VERSION ""

NS_ :

BS_:

BU_: AUT REF_ECU

BO_ 2181038088 F_EXT_0x2000008: 8 REF_ECU
 SG_ S_EXT_0x2000008_2_S32 : 39|32@0- (1,0) [-32768|32767] ""  AUT
 SG_ S_EXT_0x2000008_1_S32 : 0|32@1- (1,0) [-32768|32767] ""  AUT

BO_ 2181038087 F_EXT_0x2000007: 7 REF_ECU
 SG_ S_EXT_0x2000007_S24 : 39|24@0- (1,0) [-8388608|8388607] ""  AUT
 SG_ S_EXT_0x2000007_S32 : 7|32@0- (1,0) [-2147483648|2147483647] ""  AUT

BO_ 2181038086 F_EXT_0x2000006: 6 REF_ECU
 SG_ S_EXT_0x2000006_S16 : 39|16@0+ (1,0) [0|65535] ""  AUT
 SG_ S_EXT_0x2000006_S32 : 7|32@0- (1,0) [-2147483648|2147483647] ""  AUT

BO_ 2181038085 F_EXT_0x2000005: 5 REF_ECU
 SG_ S_EXT_0x2000005_S8 : 39|8@0+ (1,0) [0|255] ""  AUT
 SG_ S_EXT_0x2000005_S32 : 7|32@0- (1,0) [-2147483648|2147483647] ""  AUT

BO_ 2181038084 F_EXT_0x2000004: 4 REF_ECU
 SG_ S_EXT_0x2000004_S32 : 7|32@0+ (1,0) [0|4294967295] ""  AUT

BO_ 2181038083 F_EXT_0x2000003: 3 REF_ECU
 SG_ S_EXT_0x2000003_S24 : 7|24@0- (1,0) [-8388608|8388607] ""  AUT

BO_ 2181038082 F_EXT_0x2000002: 2 REF_ECU
 SG_ S_EXT_0x2000002_S16 : 7|16@0- (1,0) [-32768|32767] ""  AUT

BO_ 2181038081 F_EXT_0x2000001: 1 REF_ECU
 SG_ S_EXT_0x2000001_S8 : 7|8@0- (1,0) [-128|127] ""  AUT

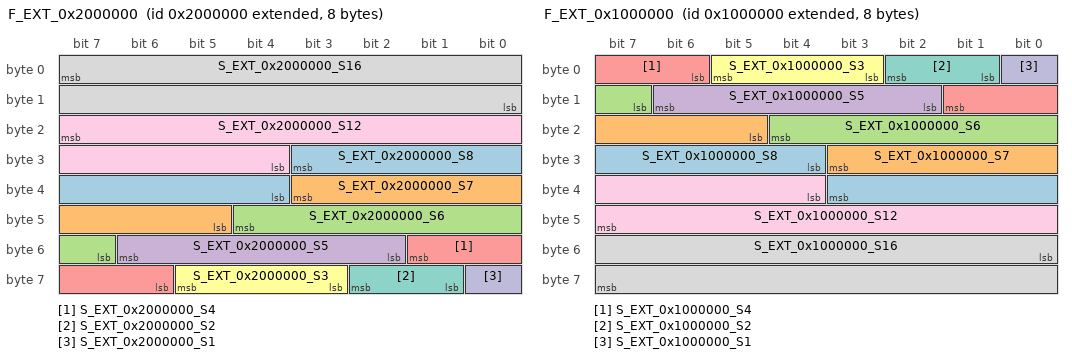
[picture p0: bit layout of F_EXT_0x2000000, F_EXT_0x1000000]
BO_ 2181038080 F_EXT_0x2000000: 8 REF_ECU
 SG_ S_EXT_0x2000000_S8 : 27|8@0- (1,0) [-128|127] ""  AUT
 SG_ S_EXT_0x2000000_S7 : 35|7@0- (1,0) [-64|63] ""  AUT
 SG_ S_EXT_0x2000000_S6 : 44|6@0- (1,0) [-32|31] ""  AUT
 SG_ S_EXT_0x2000000_S5 : 54|5@0- (1,0) [-16|15] ""  AUT
 SG_ S_EXT_0x2000000_S4 : 49|4@0- (1,0) [-8|7] ""  AUT
 SG_ S_EXT_0x2000000_S3 : 61|3@0- (1,0) [-4|3] ""  AUT
 SG_ S_EXT_0x2000000_S2 : 58|2@0- (1,0) [-2|1] ""  AUT
 SG_ S_EXT_0x2000000_S16 : 7|16@0- (1,0) [-32768|32767] ""  AUT
 SG_ S_EXT_0x2000000_S12 : 23|12@0- (1,0) [-2048|2047] ""  AUT
 SG_ S_EXT_0x2000000_S1 : 56|1@0- (1,0) [-1|0] ""  AUT

BO_ 2164260872 F_EXT_0x1000008: 8 REF_ECU
 SG_ S_EXT_0x1000008_2_S32 : 32|32@1+ (1,0) [0|4294967295] ""  AUT
 SG_ S_EXT_0x1000008_1_S32 : 0|32@1+ (1,0) [0|4294970000] ""  AUT

BO_ 2164260871 F_EXT_0x1000007: 7 REF_ECU
 SG_ S_EXT_0x1000007_S24 : 32|24@1+ (1,0) [0|16777215] ""  AUT
 SG_ S_EXT_0x1000007_S32 : 0|32@1+ (1,0) [0|4294967295] ""  AUT

BO_ 2164260870 F_EXT_0x1000006: 6 REF_ECU
 SG_ S_EXT_0x1000006_S16 : 32|16@1- (1,0) [-32768|32767] ""  AUT
 SG_ S_EXT_0x1000006_S32 : 0|32@1+ (1,0) [0|4294967295] ""  AUT

BO_ 2164260869 F_EXT_0x1000005: 5 REF_ECU
 SG_ S_EXT_0x1000005_S8 : 32|8@1- (1,0) [-128|127] ""  AUT
 SG_ S_EXT_0x1000005_S32 : 0|32@1+ (1,0) [0|4294967295] ""  AUT

BO_ 2164260868 F_EXT_0x1000004: 4 REF_ECU
 SG_ S_EXT_0x1000004_S32 : 0|32@1- (1,0) [-2147483648|2147483647] ""  AUT

BO_ 2164260867 F_EXT_0x1000003: 3 REF_ECU
 SG_ S_EXT_0x1000003_S24 : 0|24@1+ (1,0) [0|16777215] ""  AUT

BO_ 2164260866 F_EXT_0x1000002: 2 REF_ECU
 SG_ S_EXT_0x1000002_S16 : 0|16@1+ (1,0) [0|65535] ""  AUT

BO_ 2164260865 F_EXT_0x1000001: 1 REF_ECU
 SG_ S_EXT_0x1000001_S8 : 0|8@1+ (1,0) [0|255] ""  AUT

BO_ 2164260864 F_EXT_0x1000000: 8 REF_ECU
 SG_ S_EXT_0x1000000_S8 : 28|8@1+ (1,0) [0|255] ""  AUT
 SG_ S_EXT_0x1000000_S7 : 21|7@1+ (1,0) [0|127] ""  AUT
 SG_ S_EXT_0x1000000_S6 : 15|6@1+ (1,0) [0|63] ""  AUT
 SG_ S_EXT_0x1000000_S5 : 10|5@1+ (1,0) [0|31] ""  AUT
 SG_ S_EXT_0x1000000_S4 : 6|4@1+ (1,0) [0|15] ""  AUT
 SG_ S_EXT_0x1000000_S3 : 3|3@1+ (1,0) [0|7] ""  AUT
 SG_ S_EXT_0x1000000_S2 : 1|2@1+ (1,0) [0|3] ""  AUT
 SG_ S_EXT_0x1000000_S16 : 48|16@1+ (1,0) [0|65535] ""  AUT
 SG_ S_EXT_0x1000000_S12 : 36|12@1+ (1,0) [0|4095] ""  AUT
 SG_ S_EXT_0x1000000_S1 : 0|1@1+ (1,0) [0|1] ""  AUT

BO_ 776 F_STD_0x308: 8 REF_ECU
 SG_ S_STD_0x308_2_S32 : 39|32@0- (1,0) [-32768|32767] ""  AUT
 SG_ S_STD_0x308_1_S32 : 0|32@1- (1,0) [-32768|32767] ""  AUT

BO_ 775 F_STD_0x307: 7 REF_ECU
 SG_ S_STD_0x307_S24 : 39|24@0- (1,0) [-8388608|8388607] ""  AUT
 SG_ S_STD_0x307_S32 : 7|32@0- (1,0) [-2147483648|2147483647] ""  AUT

BO_ 774 F_STD_0x306: 6 REF_ECU
 SG_ S_STD_0x306_S16 : 39|16@0+ (1,0) [0|65535] ""  AUT
 SG_ S_STD_0x306_S32 : 7|32@0- (1,0) [-2147483648|2147483647] ""  AUT

BO_ 773 F_STD_0x305: 5 REF_ECU
 SG_ S_STD_0x305_S8 : 39|8@0+ (1,0) [0|255] ""  AUT
 SG_ S_STD_0x305_S32 : 7|32@0- (1,0) [-2147483648|2147483647] ""  AUT

BO_ 772 F_STD_0x304: 4 REF_ECU
 SG_ S_STD_0x304_S32 : 7|32@0+ (1,0) [0|4294967295] ""  AUT

BO_ 771 F_STD_0x303: 3 REF_ECU
 SG_ S_STD_0x303_S24 : 7|24@0- (1,0) [-8388608|8388607] ""  AUT

BO_ 770 F_STD_0x302: 2 REF_ECU
 SG_ S_STD_0x302_S16 : 7|16@0- (1,0) [-32768|32767] ""  AUT

BO_ 769 F_STD_0x301: 1 REF_ECU
 SG_ S_STD_0x301_S8 : 7|8@0- (1,0) [-128|127] ""  AUT

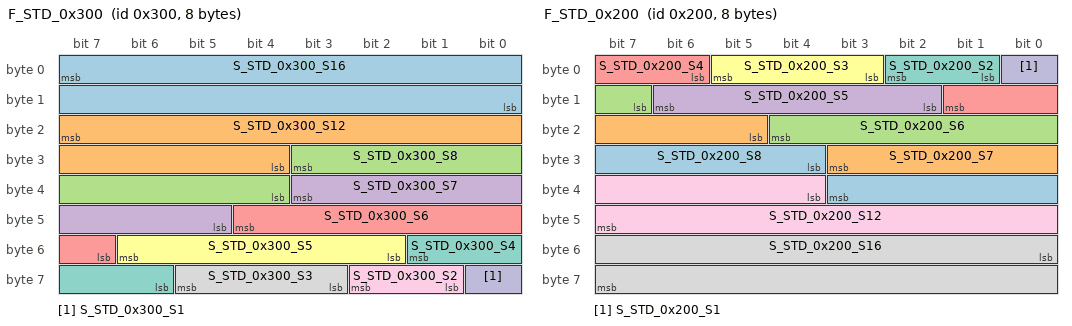
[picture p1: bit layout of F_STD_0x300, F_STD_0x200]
BO_ 768 F_STD_0x300: 8 REF_ECU
 SG_ S_STD_0x300_S16 : 7|16@0- (1,0) [-32768|32767] ""  AUT
 SG_ S_STD_0x300_S12 : 23|12@0- (1,0) [-2048|2047] ""  AUT
 SG_ S_STD_0x300_S8 : 27|8@0- (1,0) [-128|127] ""  AUT
 SG_ S_STD_0x300_S7 : 35|7@0- (1,0) [-64|63] ""  AUT
 SG_ S_STD_0x300_S6 : 44|6@0- (1,0) [-32|31] ""  AUT
 SG_ S_STD_0x300_S5 : 54|5@0- (1,0) [-16|15] ""  AUT
 SG_ S_STD_0x300_S4 : 49|4@0- (1,0) [-8|7] ""  AUT
 SG_ S_STD_0x300_S3 : 61|3@0- (1,0) [-4|3] ""  AUT
 SG_ S_STD_0x300_S2 : 58|2@0- (1,0) [-2|1] ""  AUT
 SG_ S_STD_0x300_S1 : 56|1@0- (1,0) [-1|0] ""  AUT

BO_ 520 F_STD_0x208: 8 REF_ECU
 SG_ S_STD_0x208_2_S32 : 32|32@1+ (1,0) [0|4294970000] ""  AUT
 SG_ S_STD_0x208_1_S32 : 0|32@1+ (2,4) [4|4294970000] ""  AUT

BO_ 519 F_STD_0x207: 7 REF_ECU
 SG_ S_STD_0x207_S24 : 32|24@1+ (1,0) [0|16777215] ""  AUT
 SG_ S_STD_0x207_S32 : 0|32@1+ (1,0) [0|4294970000] ""  AUT

BO_ 518 F_STD_0x206: 6 REF_ECU
 SG_ S_STD_0x206_S16 : 32|16@1- (1,0) [-32768|32767] ""  AUT
 SG_ S_STD_0x206_S32 : 0|32@1+ (1,0) [0|4294967295] ""  AUT

BO_ 517 F_STD_0x205: 5 REF_ECU
 SG_ S_STD_0x205_S8 : 32|8@1- (1,0) [-128|127] ""  AUT
 SG_ S_STD_0x205_S32 : 0|32@1+ (1,0) [0|4294970000] ""  AUT

BO_ 516 F_STD_0x204: 4 REF_ECU
 SG_ S_STD_0x204_S32 : 0|32@1- (1,0) [-2147483648|2147483647] ""  AUT

BO_ 515 F_STD_0x203: 3 REF_ECU
 SG_ S_STD_0x203_S24 : 0|24@1+ (1,0) [0|16777215] ""  AUT

BO_ 514 F_STD_0x202: 2 REF_ECU
 SG_ S_STD_0x202_S16 : 0|16@1+ (1,0) [0|65535] ""  AUT

BO_ 513 F_STD_0x201: 1 REF_ECU
 SG_ S_STD_0x201_S8 : 0|8@1+ (1,0) [0|255] ""  AUT

BO_ 512 F_STD_0x200: 8 REF_ECU
 SG_ S_STD_0x200_S8 : 28|8@1+ (1,0) [0|255] ""  AUT
 SG_ S_STD_0x200_S7 : 21|7@1+ (1,0) [0|127] ""  AUT
 SG_ S_STD_0x200_S6 : 15|6@1+ (1,0) [0|63] ""  AUT
 SG_ S_STD_0x200_S5 : 10|5@1+ (1,0) [0|31] ""  AUT
 SG_ S_STD_0x200_S4 : 6|4@1+ (1,0) [0|15] ""  AUT
 SG_ S_STD_0x200_S3 : 3|3@1+ (1,0) [0|7] ""  AUT
 SG_ S_STD_0x200_S2 : 1|2@1+ (1,0) [0|3] ""  AUT
 SG_ S_STD_0x200_S16 : 48|16@1+ (2,2) [2|131072] ""  AUT
 SG_ S_STD_0x200_S12 : 36|12@1+ (1,0) [0|4095] ""  AUT
 SG_ S_STD_0x200_S1 : 0|1@1+ (1,0) [0|1] ""  AUT

BA_DEF_  "BusType" STRING ;
BA_DEF_DEF_  "BusType" "CAN";
SIG_VALTYPE_ 2181038088 S_EXT_0x2000008_2_S32 : 1;
SIG_VALTYPE_ 2181038088 S_EXT_0x2000008_1_S32 : 1;
SIG_VALTYPE_ 776 S_STD_0x308_2_S32 : 1;
SIG_VALTYPE_ 776 S_STD_0x308_1_S32 : 1;
